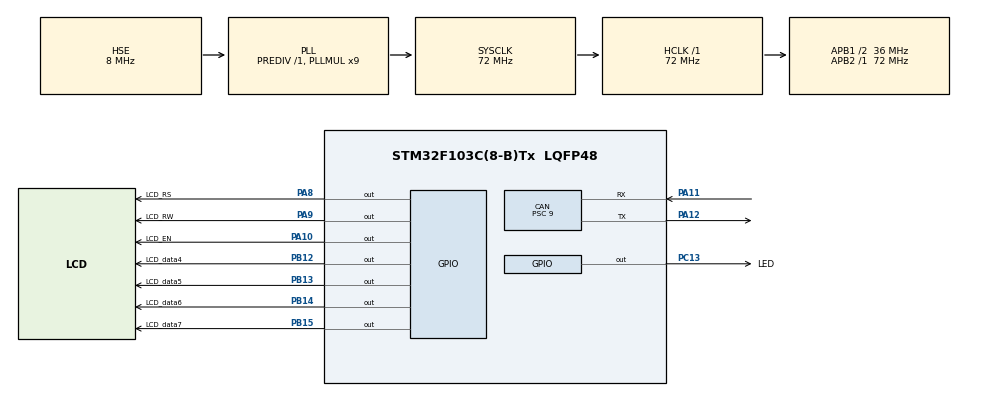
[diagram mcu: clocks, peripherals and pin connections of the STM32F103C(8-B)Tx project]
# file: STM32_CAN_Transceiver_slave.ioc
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Mcu.Family=STM32F1
RCC.PLLSourceVirtual=RCC_PLLSOURCE_HSE
PC15-OSC32_OUT.Mode=LSE-External-Oscillator
NVIC.CAN1_RX1_IRQn=true\:0\:0\:false\:false\:true\:true\:true
PD1-OSC_OUT.Mode=HSE-External-Oscillator
CAN.CalculateBaudRate=500000
PA9.GPIO_Label=LCD_RW
PB14.GPIO_Label=LCD_data6
PC13-TAMPER-RTC.Signal=GPIO_Output
PA11.Mode=CAN_Activate
PD0-OSC_IN.Signal=RCC_OSC_IN
RCC.APB1CLKDivider=RCC_HCLK_DIV2
PC14-OSC32_IN.Signal=RCC_OSC32_IN
PB13.GPIO_Label=LCD_data5
PB13.Signal=GPIO_Output
PB15.Signal=GPIO_Output
CAN.CalculateTimeBit=2000.00
RCC.SYSCLKSource=RCC_SYSCLKSOURCE_PLLCLK
ProjectManager.StackSize=0x400
PD1-OSC_OUT.Signal=RCC_OSC_OUT
PA13.Signal=SYS_JTMS-SWDIO
PA12.Signal=CAN_TX
CAN.BS2=CAN_BS2_3TQ
NVIC.USB_HP_CAN1_TX_IRQn=true\:0\:0\:false\:false\:true\:true\:true
PA8.GPIO_Label=LCD_RS
CAN.Prescaler=9
CAN.BS1=CAN_BS1_4TQ
TIM1.Prescaler=71
ProjectManager.TargetToolchain=STM32CubeIDE
RCC.HCLKFreq_Value=72000000
RCC.APB2TimFreq_Value=72000000
PA9.Signal=GPIO_Output
RCC.USBFreq_Value=72000000
CAN.Mode=CAN_MODE_SILENT_LOOPBACK
NVIC.CAN1_SCE_IRQn=true\:0\:0\:false\:false\:true\:true\:true
PC15-OSC32_OUT.Signal=RCC_OSC32_OUT
RCC.AHBFreq_Value=72000000
PD0-OSC_IN.Mode=HSE-External-Oscillator
PB14.Signal=GPIO_Output
board=custom
PC13-TAMPER-RTC.GPIO_Label=LED
RCC.PLLMUL=RCC_PLL_MUL9
PB12.GPIO_Label=LCD_data4
RCC.APB2Freq_Value=72000000
PC14-OSC32_IN.Mode=LSE-External-Oscillator
PB15.GPIO_Label=LCD_data7
PA14.Mode=Serial_Wire
NVIC.USB_LP_CAN1_RX0_IRQn=true\:0\:0\:false\:false\:true\:true\:true
CAN.NART=ENABLE
PA10.GPIO_Label=LCD_EN
PA8.Signal=GPIO_Output
PA13.Mode=Serial_Wire
Mcu.Name=STM32F103C(8-B)Tx
CAN.CalculateTimeQuantum=250.0
VP_TIM1_VS_ClockSourceINT.Mode=Internal
RCC.SYSCLKFreq_VALUE=72000000
Mcu.Package=LQFP48
PA12.Mode=CAN_Activate
PA11.Signal=CAN_RX
PA14.Signal=SYS_JTCK-SWCLK
PA10.Signal=GPIO_Output
ProjectManager.HeapSize=0x200
NVIC.PriorityGroup=NVIC_PRIORITYGROUP_4
RCC.APB1TimFreq_Value=72000000
RCC.APB1Freq_Value=36000000
PB12.Signal=GPIO_Output

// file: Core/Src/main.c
/* USER CODE BEGIN Header */
/**
  ******************************************************************************
  * @file           : main.c
  * @brief          : Main program body
  ******************************************************************************
  * @attention
  *
  * <h2><center>&copy; Copyright (c) 2021 STMicroelectronics.
  * All rights reserved.</center></h2>
  *
  * This software component is licensed by ST under BSD 3-Clause license,
  * the "License"; You may not use this file except in compliance with the
  * License. You may obtain a copy of the License at:
  *                        opensource.org/licenses/BSD-3-Clause
  *
  ******************************************************************************
  */
/* USER CODE END Header */
#include "main.h"

/* USER CODE BEGIN Includes */
#include "lcd.h"
#include "can.h"

/* USER CODE END Includes */

CAN_HandleTypeDef hcan;

TIM_HandleTypeDef htim1;

void SystemClock_Config(void);
static void MX_GPIO_Init(void);
static void MX_CAN_Init(void);
static void MX_TIM1_Init(void);

int main(void)
{

  /* MCU Configuration--------------------------------------------------------*/

  /* Reset of all peripherals, Initializes the Flash interface and the Systick. */
  HAL_Init();

  /* Configure the system clock */
  SystemClock_Config();

  /* Initialize all configured peripherals */
  MX_GPIO_Init();
  MX_CAN_Init();
  MX_TIM1_Init();
  /* USER CODE BEGIN 2 */

    HAL_TIM_Base_Start(&htim1);

    LCD_test();
    CAN_Init();
    CAN_Mytest();
  /* USER CODE END 2 */

  /* Infinite loop */
  /* USER CODE BEGIN WHILE */
    while (1) {
        HAL_GPIO_WritePin(LED_GPIO_Port, LED_Pin, 1);
        HAL_GPIO_WritePin(LED_GPIO_Port, LED_Pin, 0);
        CAN_loopTick();
    /* USER CODE END WHILE */

    }
}

void SystemClock_Config(void)
{
  RCC_OscInitTypeDef RCC_OscInitStruct = {0};
  RCC_ClkInitTypeDef RCC_ClkInitStruct = {0};

  /** Initializes the RCC Oscillators according to the specified parameters
  * in the RCC_OscInitTypeDef structure.
  */
  RCC_OscInitStruct.OscillatorType = RCC_OSCILLATORTYPE_HSE;
  RCC_OscInitStruct.HSEState = RCC_HSE_ON;
  RCC_OscInitStruct.HSEPredivValue = RCC_HSE_PREDIV_DIV1;
  RCC_OscInitStruct.HSIState = RCC_HSI_ON;
  RCC_OscInitStruct.PLL.PLLState = RCC_PLL_ON;
  RCC_OscInitStruct.PLL.PLLSource = RCC_PLLSOURCE_HSE;
  RCC_OscInitStruct.PLL.PLLMUL = RCC_PLL_MUL9;
  if (HAL_RCC_OscConfig(&RCC_OscInitStruct) != HAL_OK)
  {
    Error_Handler();
  }
  /** Initializes the CPU, AHB and APB buses clocks
  */
  RCC_ClkInitStruct.ClockType = RCC_CLOCKTYPE_HCLK|RCC_CLOCKTYPE_SYSCLK
                              |RCC_CLOCKTYPE_PCLK1|RCC_CLOCKTYPE_PCLK2;
  RCC_ClkInitStruct.SYSCLKSource = RCC_SYSCLKSOURCE_PLLCLK;
  RCC_ClkInitStruct.AHBCLKDivider = RCC_SYSCLK_DIV1;
  RCC_ClkInitStruct.APB1CLKDivider = RCC_HCLK_DIV2;
  RCC_ClkInitStruct.APB2CLKDivider = RCC_HCLK_DIV1;

  if (HAL_RCC_ClockConfig(&RCC_ClkInitStruct, FLASH_LATENCY_2) != HAL_OK)
  {
    Error_Handler();
  }
}

static void MX_CAN_Init(void)
{

  hcan.Instance = CAN1;
  hcan.Init.Prescaler = 9;
  hcan.Init.Mode = CAN_MODE_SILENT_LOOPBACK;
  hcan.Init.SyncJumpWidth = CAN_SJW_1TQ;
  hcan.Init.TimeSeg1 = CAN_BS1_4TQ;
  hcan.Init.TimeSeg2 = CAN_BS2_3TQ;
  hcan.Init.TimeTriggeredMode = DISABLE;
  hcan.Init.AutoBusOff = DISABLE;
  hcan.Init.AutoWakeUp = DISABLE;
  hcan.Init.AutoRetransmission = ENABLE;
  hcan.Init.ReceiveFifoLocked = DISABLE;
  hcan.Init.TransmitFifoPriority = DISABLE;
  if (HAL_CAN_Init(&hcan) != HAL_OK)
  {
    Error_Handler();
  }

}

static void MX_TIM1_Init(void)
{

  TIM_ClockConfigTypeDef sClockSourceConfig = {0};
  TIM_MasterConfigTypeDef sMasterConfig = {0};

  htim1.Instance = TIM1;
  htim1.Init.Prescaler = 71;
  htim1.Init.CounterMode = TIM_COUNTERMODE_UP;
  htim1.Init.Period = 65535;
  htim1.Init.ClockDivision = TIM_CLOCKDIVISION_DIV1;
  htim1.Init.RepetitionCounter = 0;
  htim1.Init.AutoReloadPreload = TIM_AUTORELOAD_PRELOAD_DISABLE;
  if (HAL_TIM_Base_Init(&htim1) != HAL_OK)
  {
    Error_Handler();
  }
  sClockSourceConfig.ClockSource = TIM_CLOCKSOURCE_INTERNAL;
  if (HAL_TIM_ConfigClockSource(&htim1, &sClockSourceConfig) != HAL_OK)
  {
    Error_Handler();
  }
  sMasterConfig.MasterOutputTrigger = TIM_TRGO_RESET;
  sMasterConfig.MasterSlaveMode = TIM_MASTERSLAVEMODE_DISABLE;
  if (HAL_TIMEx_MasterConfigSynchronization(&htim1, &sMasterConfig) != HAL_OK)
  {
    Error_Handler();
  }

}

static void MX_GPIO_Init(void)
{
  GPIO_InitTypeDef GPIO_InitStruct = {0};

  /* GPIO Ports Clock Enable */
  __HAL_RCC_GPIOC_CLK_ENABLE();
  __HAL_RCC_GPIOD_CLK_ENABLE();
  __HAL_RCC_GPIOB_CLK_ENABLE();
  __HAL_RCC_GPIOA_CLK_ENABLE();

  /*Configure GPIO pin Output Level */
  HAL_GPIO_WritePin(LED_GPIO_Port, LED_Pin, GPIO_PIN_RESET);

  /*Configure GPIO pin Output Level */
  HAL_GPIO_WritePin(GPIOB, LCD_data4_Pin|LCD_data5_Pin|LCD_data6_Pin|LCD_data7_Pin, GPIO_PIN_RESET);

  /*Configure GPIO pin Output Level */
  HAL_GPIO_WritePin(GPIOA, LCD_RS_Pin|LCD_RW_Pin|LCD_EN_Pin, GPIO_PIN_RESET);

  /*Configure GPIO pin : LED_Pin */
  GPIO_InitStruct.Pin = LED_Pin;
  GPIO_InitStruct.Mode = GPIO_MODE_OUTPUT_PP;
  GPIO_InitStruct.Pull = GPIO_NOPULL;
  GPIO_InitStruct.Speed = GPIO_SPEED_FREQ_LOW;
  HAL_GPIO_Init(LED_GPIO_Port, &GPIO_InitStruct);

  /*Configure GPIO pins : LCD_data4_Pin LCD_data5_Pin LCD_data6_Pin LCD_data7_Pin */
  GPIO_InitStruct.Pin = LCD_data4_Pin|LCD_data5_Pin|LCD_data6_Pin|LCD_data7_Pin;
  GPIO_InitStruct.Mode = GPIO_MODE_OUTPUT_PP;
  GPIO_InitStruct.Pull = GPIO_NOPULL;
  GPIO_InitStruct.Speed = GPIO_SPEED_FREQ_LOW;
  HAL_GPIO_Init(GPIOB, &GPIO_InitStruct);

  /*Configure GPIO pins : LCD_RS_Pin LCD_RW_Pin LCD_EN_Pin */
  GPIO_InitStruct.Pin = LCD_RS_Pin|LCD_RW_Pin|LCD_EN_Pin;
  GPIO_InitStruct.Mode = GPIO_MODE_OUTPUT_PP;
  GPIO_InitStruct.Pull = GPIO_NOPULL;
  GPIO_InitStruct.Speed = GPIO_SPEED_FREQ_LOW;
  HAL_GPIO_Init(GPIOA, &GPIO_InitStruct);

}

void Error_Handler(void)
{
    __disable_irq();
    while (1) {
    }
}

/************************ (C) COPYRIGHT STMicroelectronics *****END OF FILE****/
